# Template register map
Vendor: VendorName Co.Ltd; Series: SeriesName; File version: 1.2
CPU: CM7 r0p1, little endian, MPU, FPU, 4 interrupt priority bits
Registers are 32-bit, read-write, no defined reset value unless marked. A register's access mark holds for its fields unless they carry their own. Offsets are from the block's base; [hi:lo] are bit positions; {n}, {i} and the like mark numbered series.

## CLB1 — Configurable Logic Block 1
Base 0x40070000
Same registers: CLB2 0x40071000, CLB3 0x40072000, CLB4 0x40073000, CLB5 0x40074000, CLB6 0x40075000
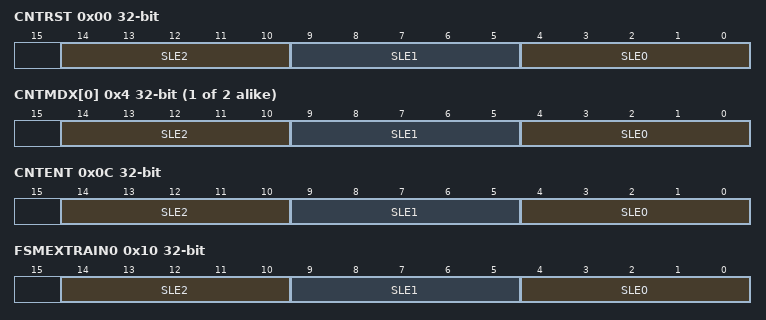
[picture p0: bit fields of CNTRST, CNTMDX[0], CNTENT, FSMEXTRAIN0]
0x00 CNTRST — CLB counter reset select inputs register
  [14:10] SLE2 — CLB SLE2[4:0] bit: counter reset select inputs for unit 2
  [9:5] SLE1 — CLB SLE1[4:0] bit: counter reset select inputs for unit 1
  [4:0] SLE0 — CLB SLE0[4:0] bit: counter reset select inputs for unit 0
{0x4+4i} CNTMDX[{i}] (i=0..1) — Grouping of CNTMD0~CNTMD1
  [14:10] SLE2 — CLB SLE2[4:0] bit: counter MODEx select inputs for unit 2
  [9:5] SLE1 — CLB SLE1[4:0] bit: counter MODEx select inputs for unit 1
  [4:0] SLE0 — CLB SLE0[4:0] bit: counter MODEx select inputs for unit 0
0x0C CNTENT — CLB counter event select inputs register
  [14:10] SLE2 — CLB SLE2[4:0] bit: counter event select inputs for unit 2
  [9:5] SLE1 — CLB SLE1[4:0] bit: counter event select inputs for unit 1
  [4:0] SLE0 — CLB SLE0[4:0] bit: counter event select inputs for unit 0
0x10 FSMEXTRAIN0 — CLB FSM block extra external IN0 select inputs register
  [14:10] SLE2 — CLB SLE2[4:0] bit: FSM block extra external IN0 select input for unit 2
  [9:5] SLE1 — CLB SLE1[4:0] bit: FSM block extra external IN0 select input for unit 1
  [4:0] SLE0 — CLB SLE0[4:0] bit: FSM block extra external IN0 select input for unit 0
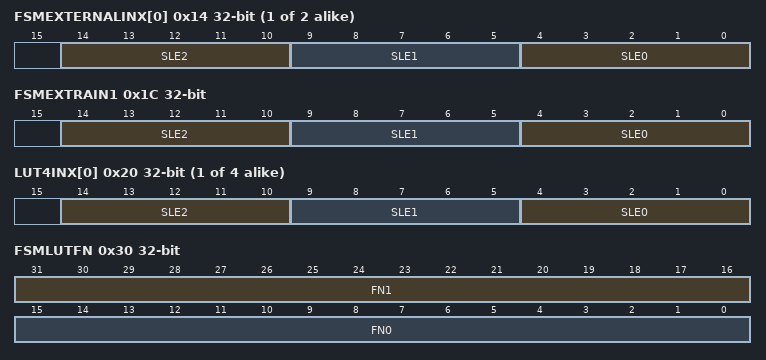
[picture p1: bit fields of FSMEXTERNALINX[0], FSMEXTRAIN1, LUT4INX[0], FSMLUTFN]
{0x14+4i} FSMEXTERNALINX[{i}] (i=0..1) — Grouping of FSMEXTERNALIN0~FSMEXTERNALIN1
  [14:10] SLE2 — CLB SLE2[4:0] bit: FSM block EXTINx select input for unit 2
  [9:5] SLE1 — CLB SLE1[4:0] bit: FSM block EXTINx select input for unit 1
  [4:0] SLE0 — CLB SLE0[4:0] bit: FSM block EXTINx select input for unit 0
0x1C FSMEXTRAIN1 — CLB FSM block extra external IN1 select inputs register
  [14:10] SLE2 — CLB SLE2[4:0] bit: FSM block extra external IN1 select input for unit 2
  [9:5] SLE1 — CLB SLE1[4:0] bit: FSM block extra external IN1 select input for unit 1
  [4:0] SLE0 — CLB SLE0[4:0] bit: FSM block extra external IN1 select input for unit 0
{0x20+4i} LUT4INX[{i}] (i=0..3) — Grouping of LUT4IN0~LUT4IN3
  [14:10] SLE2 — CLB SLE2[4:0] bit: LUT4 block INx select input for unit 2
  [9:5] SLE1 — CLB SLE1[4:0] bit: LUT4 block INx select input for unit 1
  [4:0] SLE0 — CLB SLE0[4:0] bit: LUT4 block INx select input for unit 0
0x30 FSMLUTFN — CLB FSM block LUT output function for unit 1~0
  [31:16] FN1 — CLB FN1[15:0] bit: FSM block LUT output function for unit 1
  [15:0] FN0 — CLB FN0[15:0] bit: FSM block LUT output function for unit 0
0x34 FSMLUTFN2 — CLB FSM block LUT output function for unit 2
  [15:0] FN2 — CLB FN2[15:0] bit: LUT4 output function for unit 2
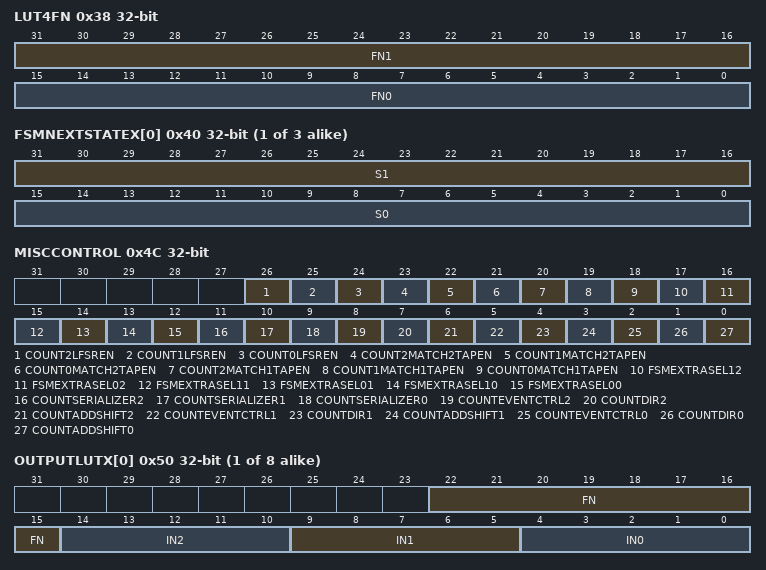
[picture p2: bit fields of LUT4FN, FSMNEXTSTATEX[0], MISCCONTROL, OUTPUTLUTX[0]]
0x38 LUT4FN — CLB LUT4 output function for unit 1~0
  [31:16] FN1 — CLB FN1[15:0] bit: LUT4 output function for unit 1
  [15:0] FN0 — CLB FN0[15:0] bit: LUT4 output function for unit 0
0x3C LUT4FN2 — CLB LUT4 output function for unit 2
  [15:0] FN2 — CLB FN2[15:0] bit: LUT4 output function for unit 2
{0x40+4i} FSMNEXTSTATEX[{i}] (i=0..2) — Grouping of FSMNEXTSTATE0~FSMNEXTSTATE2
  [31:16] S1 — CLB S1[15:0] bit: FSM next state function for S1 and unitx
  [15:0] S0 — CLB S0[15:0] bit: FSM next state function for S0 and unitx
0x4C MISCCONTROL — CLB misc control register
  [26] COUNT2LFSREN — CLB COUNT2LFSREN bit: if counter 2 should operate in LFSR mode
  [25] COUNT1LFSREN — CLB COUNT1LFSREN bit: if counter 1 should operate in LFSR mode
  [24] COUNT0LFSREN — CLB COUNT0LFSREN bit: if counter 0 should operate in LFSR mode
  [23] COUNT2MATCH2TAPEN — CLB COUNT2MATCH2TAPEN bit: if the match2 output should come from the match unit or tapped from a bit position of the counter 2
  [22] COUNT1MATCH2TAPEN — CLB COUNT1MATCH2TAPEN bit: if the match2 output should come from the match unit or tapped from a bit position of the counter 1
  [21] COUNT0MATCH2TAPEN — CLB COUNT0MATCH2TAPEN bit: if the match2 output should come from the match unit or tapped from a bit position of the counter 0
  [20] COUNT2MATCH1TAPEN — CLB COUNT2MATCH1TAPEN bit: if the match1 output should come from the match unit or tapped from a bit position of the counter 2
  [19] COUNT1MATCH1TAPEN — CLB COUNT1MATCH1TAPEN bit: if the match1 output should come from the match unit or tapped from a bit position of the counter 1
  [18] COUNT0MATCH1TAPEN — CLB COUNT0MATCH1TAPEN bit: if the match1 output should come from the match unit or tapped from a bit position of the counter 0
  [17] FSMEXTRASEL12 — CLB FSMEXTRASEL12 bit: which input should be selected for the FSM LUT of UNIT 2 1
  [16] FSMEXTRASEL02 — CLB FSMEXTRASEL02 bit: which input should be selected for the FSM LUT of UNIT 2 0
  [15] FSMEXTRASEL11 — CLB FSMEXTRASEL11 bit: which input should be selected for the FSM LUT of UNIT 1 1
  [14] FSMEXTRASEL01 — CLB FSMEXTRASEL01 bit: which input should be selected for the FSM LUT of UNIT 1 0
  [13] FSMEXTRASEL10 — CLB FSMEXTRASEL10 bit: which input should be selected for the FSM LUT of UNIT 0 1
  [12] FSMEXTRASEL00 — CLB FSMEXTRASEL00 bit: which input should be selected for the FSM LUT of UNIT 0 0
  [11] COUNTSERIALIZER2 — CLB COUNTSERIALIZER2 bit: controls if the counter of UNIT 2 is the serialzer mode or not
  [10] COUNTSERIALIZER1 — CLB COUNTSERIALIZER1 bit: controls if the counter of UNIT 1 is the serialzer mode or not
  [9] COUNTSERIALIZER0 — CLB COUNTSERIALIZER0 bit: controls if the counter of UNIT 0 is the serialzer mode or not
  [8] COUNTEVENTCTRL2 — CLB COUNTEVENTCTRL2 bit: controls the actions on an EVENT for UNIT2
  [7] COUNTDIR2 — CLB COUNTDIR2 bit: controls add/shift direction for UNIT 2
  [6] COUNTADDSHIFT2 — CLB COUNTADDSHIFT2 bit: controls whether the UNIT 2 counter will do an ADD or a SHIFT on an EVENT
  [5] COUNTEVENTCTRL1 — CLB COUNTEVENTCTRL1 bit: controls the actions on an EVENT for UNIT1
  [4] COUNTDIR1 — CLB COUNTDIR1 bit: controls add/shift direction for UNIT 1
  [3] COUNTADDSHIFT1 — CLB COUNTADDSHIFT1 bit: controls whether the UNIT 1 counter will do an ADD or a SHIFT on an EVENT
  [2] COUNTEVENTCTRL0 — CLB COUNTEVENTCTRL0 bit: controls the actions on an EVENT for UNIT0
  [1] COUNTDIR0 — CLB COUNTDIR0 bit: controls add/shift direction for UNIT 0
  [0] COUNTADDSHIFT0 — CLB COUNTADDSHIFT0 bit: controls whether the UNIT 0 counter will do an ADD or a SHIFT on an EVENT
{0x50+4i} OUTPUTLUTX[{i}] (i=0..7) — Grouping of OUTPUTLUT0~OUTPUTLUT7
  [22:15] FN — CLB FN[7:0] bit: output function for output LUTx
  [14:10] IN2 — CLB IN2[4:0] bit: select value for IN2 of output LUTx
  [9:5] IN1 — CLB IN1[4:0] bit: select value for IN1 of output LUTx
  [4:0] IN0 — CLB IN0[4:0] bit: select value for IN0 of output LUTx
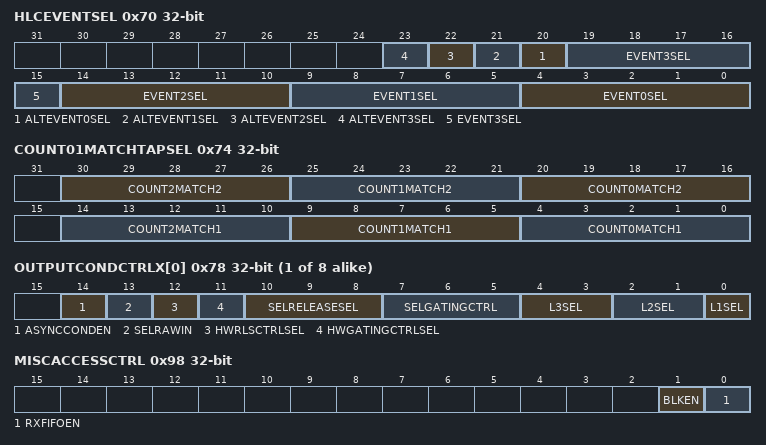
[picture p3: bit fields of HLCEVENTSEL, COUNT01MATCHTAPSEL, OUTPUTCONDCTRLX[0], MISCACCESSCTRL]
0x70 HLCEVENTSEL — CLB defines selection of alternate inputs for EVENT0~3 high level controller
  [n+20] ALTEVENT{n}SEL (n=0..3) — CLB ALTEVENT{n}SEL bit: defines selection of alternate inputs for EVENT{n}
  [5n+4:5n] EVENT{n}SEL (n=0..3) — CLB EVENT{n}SEL[4:0] bit: 5 bit select value for EVENT{n} of the high level controller
0x74 COUNT01MATCHTAPSEL — CLB MUX select for match tap for counter unit 0~2
  [30:26] COUNT2MATCH2 — CLB COUNT2MATCH2[4:0] bit: 5 bit MUX select for match1 tap for counter unit 2
  [25:21] COUNT1MATCH2 — CLB COUNT1MATCH2[4:0] bit: 5 bit MUX select for match1 tap for counter unit 1
  [20:16] COUNT0MATCH2 — CLB COUNT0MATCH2[4:0] bit: 5 bit MUX select for match1 tap for counter unit 0
  [14:10] COUNT2MATCH1 — CLB COUNT2MATCH1[4:0] bit: 5 bit MUX select for match0 tap for counter unit 2
  [9:5] COUNT1MATCH1 — CLB COUNT1MATCH1[4:0] bit: 5 bit MUX select for match0 tap for counter unit 1
  [4:0] COUNT0MATCH1 — CLB COUNT0MATCH1[4:0] bit: 5 bit MUX select for match0 tap for counter unit 0
{0x78+4i} OUTPUTCONDCTRLX[{i}] (i=0..7) — Grouping of OUTPUTLUTCONDCTRL0~OUTPUTLUTCONDCTRL7
  [14] ASYNCCONDEN — CLB ASYNCCONDEN bit: controls whether the output will pass through the asynchronous conditioning block or bypass it
  [13] SELRAWIN — CLB SELRAWIN bit: controls whether the CELL outputs or inputs are sent to the output conditioning block logic
  [12] HWRLSCTRLSEL — CLB HWRLSCTRLSEL bit: controls whether the HW or software will act as the release control
  [11] HWGATINGCTRLSEL — CLB HWGATINGCTRLSEL bit: controls whether the HW or software will act as the gating control
  [10:8] SELRELEASESEL — CLB SELRELEASESEL[2:0] bit: 3 bit MUX selects which will select one of the 8 CELL outputs for release control
  [7:5] SELGATINGCTRL — CLB SELGATINGCTRL[2:0] bit: 3 bit MUX selects which will select one of the 8 CELL outputs for gating control
  [4:3] L3SEL — CLB L3SEL[1:0] bit: controls third level Mux select
  [2:1] L2SEL — CLB L2SEL[1:0] bit: controls second level Mux select
  [0] L1SEL — CLB L1SEL bit: first level MUX select value
0x98 MISCACCESSCTRL — CLB misc access control register
  [1] BLKEN — CLB BLKEN bit: this bit is used to block writes to CLBOUTEN
  [0] RXFIFOEN — CLB RXFIFOEN bit: this bit indicates the status of the data FIFO ability to export CLB output data
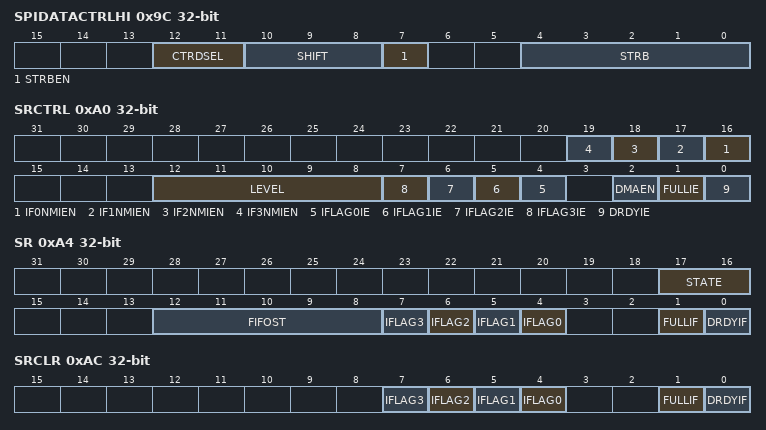
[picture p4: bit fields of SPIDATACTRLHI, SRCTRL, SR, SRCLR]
0x9C SPIDATACTRLHI — CLB spi data control high part register
  [12:11] CTRDSEL — CLB CTRDSEL[1:0] bit: when STRBEN=1 data selected to load
  [10:8] SHIFT — CLB SHIFT[2:0] bit: this is a 3 bit value which be load to FIFO
  [7] STRBEN — CLB STRBEN bit: whether to enable the selceted pulse event
  [4:0] STRB — CLB STRB[4:0] bit: this is a 5 bit value which selects one of the HLCEVENT inputs to be treated as the data valid strobe
0xA0 SRCTRL — CLB state control register
  [n+16] IF{n}NMIEN (n=0..3) — CLB IF{n}NMIEN bit: active when NEWCFG.nmiopt=1 {n}
  [12:8] LEVEL — CLB LEVEL[4:0] bit: level selection bit
  [n+4] IFLAG{n}IE (n=0..3) — CLB IFLAG{n}IE bit: interrupt flag {n} enable bit
  [2] DMAEN ro — CLB DMAEN bit: DMA enable
  [1] FULLIE — CLB FULLIE bit: full interrupt enable
  [0] DRDYIE — CLB DRDYIE bit: data ready interrupt enable
0xA4 SR ro — CLB state register
  [17:16] STATE — CLB STATE[1:0] bit: FIFO state enable bit
  [12:8] FIFOST — CLB FIFOST[4:0] bit: data number in FIFO
  [n+4] IFLAG{n} (n=0..3) — CLB IFLAG{n} bit: interrupt flag for event {n}
  [1] FULLIF — CLB FULLIF bit: full interrupt flag
  [0] DRDYIF — CLB DRDYIF bit: data ready interrupt flag
0xA8 DATAFIFO ro — CLB data FIFO register
  [31:0] RDATA — CLB RDATA[31:0] bit: FIFO data
0xAC SRCLR wo — CLB state clear register
  [n+4] IFLAG{n} (n=0..3) — CLB IFLAG{n} bit: interrupt clear flag for event {n}
  [1] FULLIF — CLB FULLIF bit: full interrupt clear flag
  [0] DRDYIF — CLB DRDYIF bit: data ready interrupt clear flag
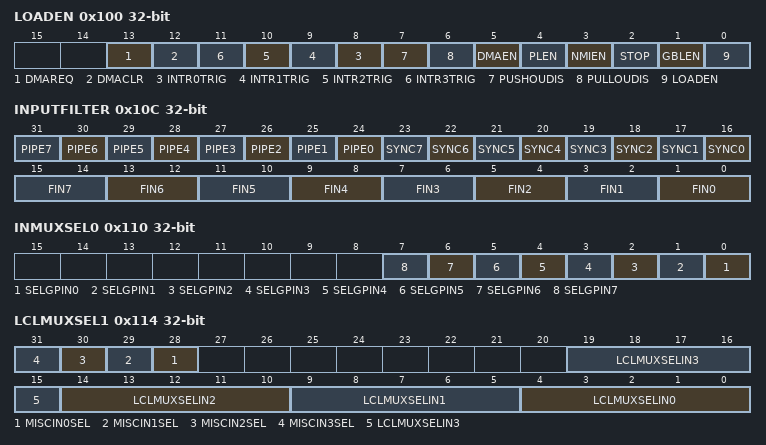
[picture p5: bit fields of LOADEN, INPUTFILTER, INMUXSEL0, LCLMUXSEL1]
0x100 LOADEN — CLB state clear register
  [13] DMAREQ wo — CLB DMAREQ bit: DMA request trig bit
  [12] DMACLR wo — CLB DMACLR bit: DMA request clear bit
  [n+8] INTR{n}TRIG wo (n=0..3) — CLB INTR{n}TRIG bit: interrupt {n} flag trig
  [7] PUSHOUDIS — CLB PUSHOUDIS bit: push FIFO overflow and underflow detection disable
  [6] PULLOUDIS — CLB PULLOUDIS bit: pull FIFO overflow and underflow detection disable
  [5] DMAEN — CLB DMAEN bit: DMA request enable bit
  [4] PLEN — CLB PLEN bit: this bit controls pipelining of all the CLB operations in HLC and counter blocks
  [3] NMIEN — CLB NMIEN bit: this bit controls the generation of NMI
  [2] STOP — CLB STOP bit: this bit defines the behaviour of the sequential elements in the CELL
  [1] GBLEN — CLB GBLEN bit: this bit is a global enable signal for the logic in the CELL
  [0] LOADEN — CLB LOADEN bit: the indirect register of CELL loading signal enable bit
0x104 LOADADDR — CLB load address register
  [4:0] ADDR — CLB ADDR[4:0] bit: these are the address bits used for writing to the indirect address space of the CELL
0x108 LOADDATA — CLB load data register
  [31:0] DATA — CLB DATA[31:0] bit: this register holds the 32-bit data for writing to the indirect address space of the CELL
0x10C INPUTFILTER — CLB input filter register
  [n+24] PIPE{n} (n=0..7) — CLB PIPE{n} bit: enable pipelining for input {n}
  [n+16] SYNC{n} (n=0..7) — CLB SYNC{n} bit: synchronizer select control for input {n}
  [2n+1:2n] FIN{n} (n=0..7) — CLB FIN{n}[1:0] bit: input filter selection for CELL input {n}
0x110 INMUXSEL0 — CLB input filter register
  [n] SELGPIN{n} (n=0..7) — CLB SELGPIN{n} bit: select control for input 7 to decide between external input and CLBGPREG {n}
0x114 LCLMUXSEL1 — CLB LCL mux selection register 1
  [n+28] MISCIN{n}SEL (n=0..3) — CLB MISCIN{n}SEL bit: the range selection of LCLMUXSELIN{n}
  [5n+4:5n] LCLMUXSELIN{n} (n=0..3) — CLB LCLMUXSELIN{n}[4:0] bit: 5 bit MUX select for local MUX control for input {n}
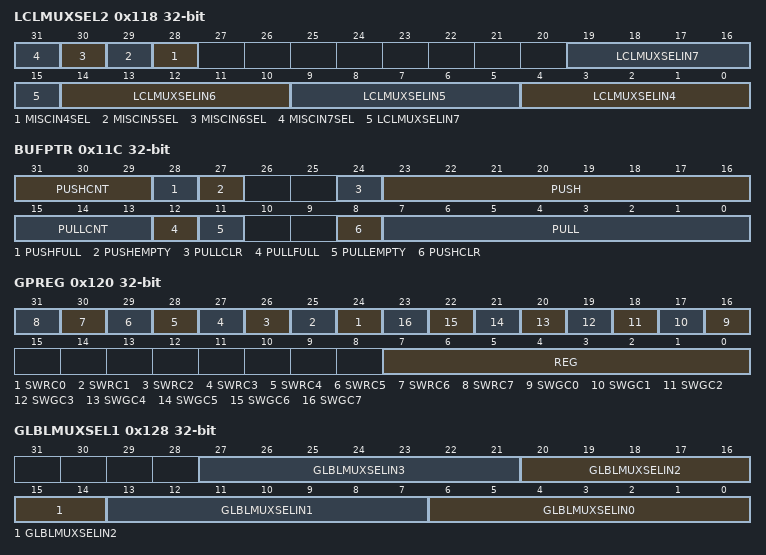
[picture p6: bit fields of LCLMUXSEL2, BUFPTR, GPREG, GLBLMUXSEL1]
0x118 LCLMUXSEL2 — CLB LCL mux selection register 2
  [n+24] MISCIN{n}SEL (n=4..7) — CLB MISCIN{n}SEL bit: the range selection of LCLMUXSELIN{n}
  [5n-16:5n-20] LCLMUXSELIN{n} (n=4..7) — CLB LCLMUXSELIN{n}[4:0] bit: 5 bit MUX select for local MUX control for input {n}
0x11C BUFPTR — CLB buffer pull/push register
  [31:29] PUSHCNT ro — CLB PUSHCNT[2:0] bit: push FIFO pointer
  [28] PUSHFULL ro — CLB PUSHFULL bit: push FIFO full flag
  [27] PUSHEMPTY ro — CLB PUSHEMPTY bit: push FIFO empty flag
  [24] PULLCLR wo — CLB PULLCLR bit: clear push FIFO
  [23:16] PUSH — CLB PUSH[7:0] bit: push data value
  [15:13] PULLCNT ro — CLB PULLCNT[2:0] bit: pull FIFO pointer
  [12] PULLFULL ro — CLB PULLFULL bit: pull FIFO full flag
  [11] PULLEMPTY ro — CLB PULLEMPTY bit: pull FIFO empty flag
  [8] PUSHCLR wo — CLB PUSHCLR bit: pull data value
  [7:0] PULL — CLB PULL[7:0] bit: CLB PULL[7:0] bit:data values
0x120 GPREG — CLB release/gating control for output 0~7 register
  [n+24] SWRC{n} (n=0..7) — CLB SWRC{n} bit: software release control for output {n} of the asynchronous output conditioning block
  [n+16] SWGC{n} (n=0..7) — CLB SWGC{n} bit: software gating control for output {n} of the asynchronous output conditioning block
  [7:0] REG — CLB REG[7:0] bit: 8 bits which are directly connected to the 8 inputs of the CELL
0x124 OUTEN — CLB output enable register
  [31:0] OUT0 — CLB OUT0[31:0] bit: 32 bits which are directly driven out as OUTPUTEN signals
0x128 GLBLMUXSEL1 — CLB globle mux selection register 1
  [7n+6:7n] GLBLMUXSELIN{n} (n=0..3) — CLB GLBLMUXSELIN{n}[6:0] bit: 7 bit MUX select for global MUX control for input {n} see global signals and MUX selection table
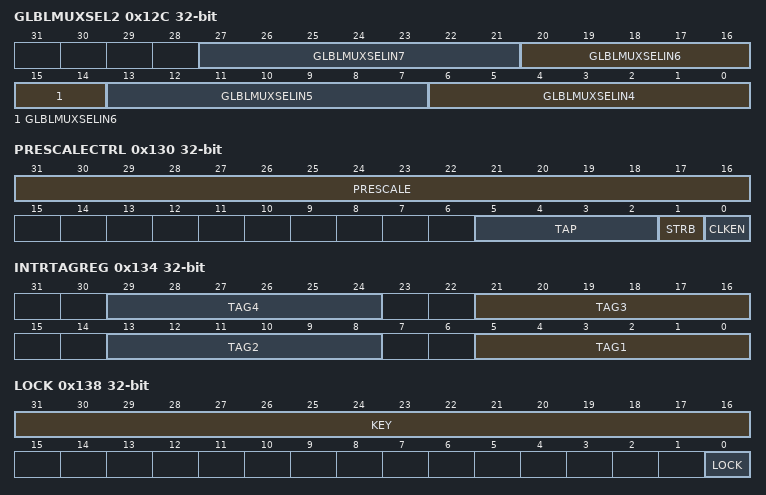
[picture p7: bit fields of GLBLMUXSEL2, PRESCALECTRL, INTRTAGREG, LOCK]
0x12C GLBLMUXSEL2 — CLB globle mux selection register 2
  [7n-22:7n-28] GLBLMUXSELIN{n} (n=4..7) — CLB GLBLMUXSELIN{n}[6:0] bit: 7 bit MUX select for global MUX control for input {n} see global signals and MUX selection table
0x130 PRESCALECTRL — CLB prescale control register
  [31:16] PRESCALE — CLB PRESCALE[15:0] bit: 16-bit value of prescaler to be used for the counter as reference to reset when reaching this value
  [5:2] TAP — CLB TAP[3:0] bit: TAP select value
  [1] STRB — CLB STRB bit: send out result bit
  [0] CLKEN — CLB CLKEN bit: enable the prescale clock or strobe generator
0x134 INTRTAGREG — CLB interrupt target register
  [8n-3:8n-8] TAG{n} (n=1..4) — CLB TAG{n}[5:0] bit: 6 bits which are used by the high level controller to set a tag {n}
0x138 LOCK — CLB locker register
  [31:16] KEY wo — CLB KEY[15:0] bit: only when 0x5A5A is written can this register be written
  [0] LOCK — CLB LOCK bit: this bit is used as a one-time write bit
0x13C HLCINSTRREADPTR — CLB read out HLC instruction register
  [4:0] RPTR — CLB RPTR[4:0] bit: this is a 5 bit value which will be used as an address pointer to read out HLC instruction memory
0x140 HLCINSTRVALUE ro — CLB HLC instruction value register
  [11:0] INSTR — CLB INSTR[11:0] bit: this is a 12 bit value which will read the content of the HLC instruction memory address pointed by CLBHLCINSTRREADPTR register
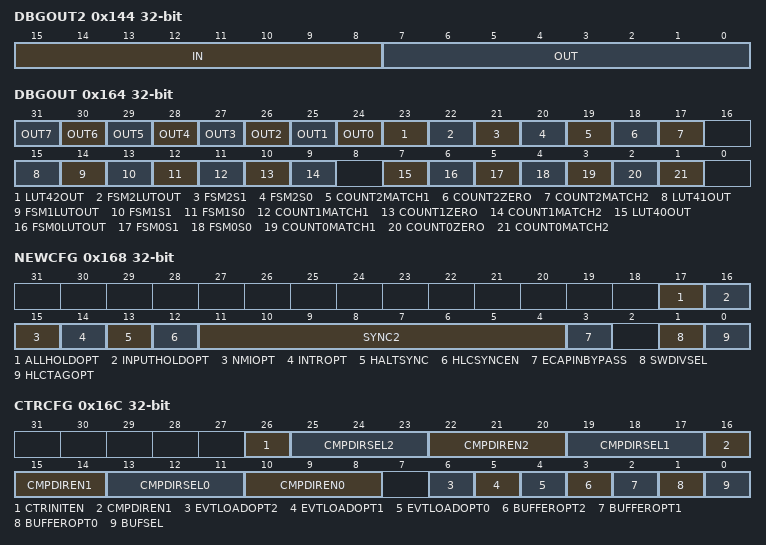
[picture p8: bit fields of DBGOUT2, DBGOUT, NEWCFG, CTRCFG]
0x144 DBGOUT2 ro — CLB debug output register 2
  [15:8] IN — CLB IN[7:0] bit: these bits reflect the state of the 8 inputs finally going to the CELL after selection and input conditioning
  [7:0] OUT — CLB OUT[7:0] bit: these bits reflect the state of the 8 outputs of the output conditioning block
{0x148+4i} DBGRX[{i}] (i=0..3) ro — Grouping of DBGR0~DBGR3
  [31:0] DBGR — CLB DBGR[31:0] bit: debug Rx
{0x158+4i} DBGCX[{i}] (i=0..2) ro — Grouping of DBGC0~DBGC2
  [31:0] DBGC — CLB DBGC[31:0] bit: debug Cx
0x164 DBGOUT ro — CLB debug output register
  [n+24] OUT{n} (n=0..7) — CLB OUT{n} bit: CELL output {n}
  [23] LUT42OUT — CLB LUT42OUT bit: LUT4 output unit 2
  [22] FSM2LUTOUT — CLB FSM2LUTOUT bit: FSMLUToutput unit 2
  [21] FSM2S1 — CLB FSM2S1 bit: FSM S1 unit 2
  [20] FSM2S0 — CLB FSM2S0 bit: FSM S0 unit 2
  [19] COUNT2MATCH1 — CLB COUNT2MATCH1 bit: COUNT MATCH1 unit 2
  [18] COUNT2ZERO — CLB COUNT2ZERO bit: COUNT ZERO unit 2
  [17] COUNT2MATCH2 — CLB COUNT2MATCH2 bit: COUNT MATCH2 unit 2
  [15] LUT41OUT — CLB LUT41OUT bit: LUT4 output unit 1
  [14] FSM1LUTOUT — CLB FSM1LUTOUT bit: FSMLUToutput unit 1
  [13] FSM1S1 — CLB FSM1S1 bit: FSM S1 unit 1
  [12] FSM1S0 — CLB FSM1S0 bit: FSM S0 unit 1
  [11] COUNT1MATCH1 — CLB COUNT1MATCH1 bit: COUNT MATCH1 unit 1
  [10] COUNT1ZERO — CLB COUNT1ZERO bit: COUNT ZERO unit 1
  [9] COUNT1MATCH2 — CLB COUNT1MATCH2 bit: COUNT MATCH2 unit 1
  [7] LUT40OUT — CLB LUT40OUT bit: LUT4 output unit 0
  [6] FSM0LUTOUT — CLB FSM0LUTOUT bit: FSMLUToutput unit 0
  [5] FSM0S1 — CLB FSM0S1 bit: FSM S1 unit 0
  [4] FSM0S0 — CLB FSM0S0 bit: FSM S0 unit 0
  [3] COUNT0MATCH1 — CLB COUNT0MATCH1 bit: COUNT MATCH1 unit 0
  [2] COUNT0ZERO — CLB COUNT0ZERO bit: COUNTZERO unit 0
  [1] COUNT0MATCH2 — CLB COUNT0MATCH2 bit: COUNT MATCH2 unit 0
0x168 NEWCFG — CLB new config register
  [17] ALLHOLDOPT — CLB ALLHOLDOPT bit: all sequence circuit hold option bit
  [16] INPUTHOLDOPT — CLB INPUTHOLDOPT bit: boundary input hold option bit
  [15] NMIOPT — CLB NMIOPT bit: NMI control option bit
  [14] INTROPT — CLB INTROPT bit: interrupt option bit
  [13] HALTSYNC — CLB HALTSYNC bit: CPU2 halt input select bit
  [12] HLCSYNCEN — CLB HLCSYNCEN bit: asychronous 3-beat enable
  [11:4] SYNC2 — CLB SYNC2[7:0] bit: AOC hardware release and gating signal beat select bit
  [3] ECAPINBYPASS — CLB ECAPINBYPASS bit: ecapin input synchronous function enable
  [1] SWDIVSEL — CLB SWDIVSEL bit: CLB module frequency division enable
  [0] HLCTAGOPT — CLB HLCTAGOPT bit: HLC tag option bit
0x16C CTRCFG — CLB current config register
  [26] CTRINITEN — CLB CTRINITEN bit: not define
  [25:23] CMPDIRSEL2 — CLB CMPDIRSEL2[2:0] bit: CTR2 series increase or decrease comparation select
  [22:20] CMPDIREN2 — CLB CMPDIREN2[2:0] bit: CTR2 series comparation and direction correlation enable control
  [19:17] CMPDIRSEL1 — CLB CMPDIRSEL1[2:0] bit: CTR1 series increase or decrease comparation select
  [16:14] CMPDIREN1 — CLB CMPDIREN1[2:0] bit: CTR1 series comparation and direction correlation enable control
  [13:11] CMPDIRSEL0 — CLB CMPDIRSEL0[2:0] bit: CTR0 series increase or decrease comparation select
  [10:8] CMPDIREN0 — CLB CMPDIREN0[2:0] bit: CTR0 series comparation and direction correlation enable control
  [6] EVTLOADOPT2 — CLB EVTLOADOPT2 bit: whether judge event 2 signal when counter 2 load buffer
  [5] EVTLOADOPT1 — CLB EVTLOADOPT1 bit: whether judge event 1 signal when counter 1 load buffer
  [4] EVTLOADOPT0 — CLB EVTLOADOPT0 bit: whether judge event 0 signal when counter 0 load buffer
  [3] BUFFEROPT2 — CLB BUFFEROPT2 bit: whether judge mode 2 signal when counter 2 load buffer
  [2] BUFFEROPT1 — CLB BUFFEROPT1 bit: whether judge mode 1 signal when counter 1 load buffer
  [1] BUFFEROPT0 — CLB BUFFEROPT0 bit: whether judge mode 0 signal when counter 0 load buffer
  [0] BUFSEL — CLB BUFSEL bit: the value of CTR select bit
{0x170+4i} PUSHX[{i}] (i=0..3) ro — Grouping of PUSH0~PUSH3
  [31:0] PUSH — CLB PUSH[31:0] bit: FIFO to system from CLB x
{0x190+4i} PULLX[{i}] (i=0..3) — Grouping of PULL0~PULL3
  [31:0] PULL — CLB PULL[31:0] bit: CLB PULL[31:0] bit:FIFO from system to CLB x
0x1F4 PUSH ro — FIFO to system from CLB
  [31:0] PUSH — CLB PUSH[31:0] bit: FIFO to system from CLB
0x1F8 PULL — FIFO from system to CLB
  [31:0] PULL — CLB PULL[31:0] bit: FIFO from system to CLB
